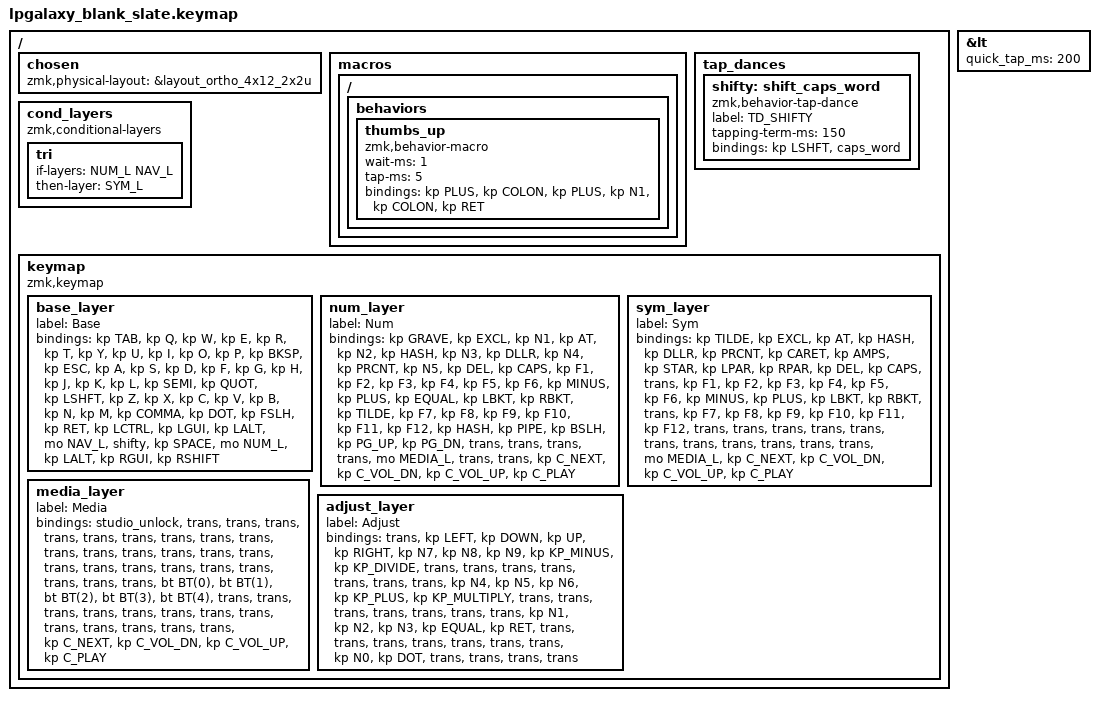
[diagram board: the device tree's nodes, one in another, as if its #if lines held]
/*
 * Copyright (c) 2022 Pete Johanson
 *
 * SPDX-License-Identifier: MIT
 */

#include <behaviors.dtsi>
#include <dt-bindings/zmk/keys.h>
#include <dt-bindings/zmk/bt.h>
#include <dt-bindings/zmk/outputs.h>

#define QWERTY_BASE 1

//#define TBLE_ORTHO   1
#define TBLE_MIT     1
// #define TBLE_DUAL_2U 1

// #define NAV_L 1
#define NUM_L 1
#define SYM_L 2
#define MEDIA_L 3
#define ADJUST_L 4


// Using layer taps on thumbs, having quick tap as well helps w/ repeating space/backspace
&lt { quick_tap_ms = <200>; };

#define BT(n) BT_SEL n

/ {
    chosen {
       zmk,physical-layout =
#ifdef TBLE_DUAL_2U
                       &layout_ortho_4x12_2x2u;
#elif defined(TBLE_MIT)
                       &layout_ortho_4x12_1x2u;
#else
                       &layout_ortho_4x12_all1u;
#endif
    };

    macros {
      ZMK_MACRO(thumbs_up,
		wait-ms = <1>;
		tap-ms = <5>;
                bindings = <&kp PLUS &kp COLON &kp PLUS &kp N1 &kp COLON &kp RET>;
		)
    };
    
    tap_dances {
    	shifty: shift_caps_word {
		compatible = "zmk,behavior-tap-dance";
		label = "TD_SHIFTY";
		#binding-cells = <0>;
		tapping-term-ms = <150>;
		bindings = <&kp LSHFT>, <&caps_word>;
	};
    };

// Conditional layer only when we have less thumb keys
#ifdef TBLE_DUAL_2U
    cond_layers {
        compatible = "zmk,conditional-layers";
	tri {
	    if-layers = <NUM_L NAV_L>;
	    then-layer = <SYM_L>;
        };
    };
#endif

    keymap {
        compatible = "zmk,keymap";

        base_layer {
            label = "Base";
            bindings = <
#ifdef QWERTY_BASE
 &kp TAB    &kp Q      &kp W      &kp E       &kp R          &kp T          &kp Y            &kp U          &kp I       &kp O      &kp P         &kp BKSP
 &kp ESC    &kp A      &kp S      &kp D       &kp F          &kp G          &kp H            &kp J          &kp K       &kp L      &kp SEMI      &kp QUOT
 &kp LSHFT  &kp Z      &kp X      &kp C       &kp V          &kp B          &kp N            &kp M          &kp COMMA   &kp DOT    &kp FSLH      &kp RET

#else
 &kp ESC    &kp Q      &kp W      &kp F       &kp P          &kp B          &kp J            &kp L          &kp U       &kp Y      &kp QUOT      &kp BKSP
 &kp TAB    &kp A      &kp R      &kp S       &kp T          &kp G          &kp M            &kp N          &kp E       &kp I      &kp O         &kp QUOT
 &kp LSHFT  &kp Z      &kp X      &kp C       &kp D          &kp V          &kp K            &kp H          &kp COMMA   &kp DOT    &kp SEMI      &kp RET
#endif
#ifdef TBLE_DUAL_2U
 &kp LCTRL  &kp LGUI   &kp LALT   &mo NAV_L         &shifty                        &kp SPACE                &mo NUM_L   &kp LALT   &kp RGUI      &kp RSHIFT

#elif defined(TBLE_MIT)
// &kp LCTRL  &mo SYM_L   &kp LGUI  &kp LALT    &mo NAV_L          &kp SPACE                   &mo NUM_L      &kp LEFT    &kp DOWN     &kp UP      &kp RIGHT
// &kp LCTRL  &kp LGUI  &kp LALT  &tog ADJUST_L  &mo SYM_L            &kp SPACE                   &mo NUM_L      &kp LEFT    &kp DOWN     &kp UP      &kp RIGHT
   &kp LCTRL  &kp LGUI  &kp LALT  &mo ADJUST_L  &mo SYM_L            &kp SPACE                &mo NUM_L      &kp LEFT    &kp DOWN     &kp UP      &kp RIGHT
#else
&kp LCTRL  &mo SYM_L   &kp LGUI  &kp LALT    &mo NAV_L      &kp SPACE      &kp RET          &mo NUM_L      &kp LEFT    &kp UP     &kp DOWN      &kp RIGHT
//   &kp LCTRL  &kp LGUI  &kp LALT  &tog ADJUST_L  &mo SYM_L            &kp SPACE              &mo NUM_L      &kp LEFT    &kp DOWN     &kp UP      &kp RIGHT
#endif
            >;
        };
//           --------------------------- NEW NUM ---------------------------
num_layer {
    label = "Num";
    bindings = <
 &kp GRAVE   &kp EXCL  &kp N1     &kp AT      &kp N2         &kp HASH       &kp N3           &kp DLLR       &kp N4      &kp PRCNT  &kp N5        &kp DEL
 &kp CAPS    &kp F1    &kp F2     &kp F3      &kp F4         &kp F5         &kp F6           &kp MINUS      &kp PLUS    &kp EQUAL  &kp LBKT      &kp RBKT
 &kp TILDE   &kp F7    &kp F8     &kp F9      &kp F10        &kp F11        &kp F12          &kp HASH       &kp PIPE    &kp BSLH   &kp PG_UP     &kp PG_DN
 &trans      &trans    &trans     &trans      &mo MEDIA_L            &trans                  &trans         &kp C_NEXT  &kp C_VOL_DN &kp C_VOL_UP &kp C_PLAY
    >;
};

//           --------------------------- NEW SYM ---------------------------
sym_layer {
    label = "Sym";
    bindings = <
 &kp TILDE  &kp EXCL   &kp AT     &kp HASH    &kp DLLR       &kp PRCNT      &kp CARET        &kp AMPS       &kp STAR    &kp LPAR   &kp RPAR      &kp DEL
 &kp CAPS   &trans     &kp F1     &kp F2      &kp F3         &kp F4         &kp F5           &kp F6         &kp MINUS   &kp PLUS   &kp LBKT      &kp RBKT
 &trans     &kp F7     &kp F8     &kp F9      &kp F10        &kp F11        &kp F12          &trans         &trans      &trans     &trans        &trans
 &trans     &trans     &trans     &trans      &trans                &trans                   &mo MEDIA_L    &kp C_NEXT  &kp C_VOL_DN &kp C_VOL_UP &kp C_PLAY
    >;
};
//           --------------------------- NEW MEDIA ---------------------------
media_layer {
    label = "Media";
    bindings = <
 &studio_unlock     &trans     &trans     &trans      &trans         &trans         &trans           &trans         &trans      &trans     &trans        &trans
 &trans     &trans     &trans     &trans      &trans         &trans         &trans           &trans         &trans      &trans     &trans        &trans
 &trans     &bt BT(0)  &bt BT(1)  &bt BT(2)   &bt BT(3)      &bt BT(4)      &trans           &trans         &trans      &trans     &trans        &trans
 &trans     &trans     &trans     &trans      &trans                 &trans                  &trans         &kp C_NEXT  &kp C_VOL_DN &kp C_VOL_UP &kp C_PLAY
    >;
};
//           --------------------------- NEW ADJUST ---------------------------
adjust_layer {
    label = "Adjust";
    bindings = <
&trans     &kp LEFT   &kp DOWN   &kp UP      &kp RIGHT       &kp N7          &kp N8          &kp N9          &kp KP_MINUS      &kp KP_DIVIDE       &trans        &trans
&trans     &trans     &trans     &trans      &trans          &kp N4          &kp N5          &kp N6          &kp KP_PLUS       &kp KP_MULTIPLY     &trans        &trans
&trans     &trans     &trans     &trans      &trans          &kp N1          &kp N2          &kp N3          &kp EQUAL         &kp RET             &trans        &trans
&trans     &trans     &trans     &trans      &trans                 &kp N0                   &kp DOT         &trans            &trans              &trans        &trans
    >;
};
    };
};

//           --------------------------- OLD NAV ---------------------------
//        nav_layer {
//            label = "Nav";
//            bindings = <
//&bt BT_CLR &trans     &trans     &trans      &trans          &trans       &trans     &trans         &trans      &trans     &trans     &kp DEL
//&trans     &trans     &trans     &trans      &trans          &trans       &trans     &kp LEFT       &kp DOWN    &kp UP     &kp RIGHT  &trans
//&trans     &bt BT(0)  &bt BT(1)  &bt BT(2)   &bt BT(3)       &bt BT(4)    &trans     &kp HOME       &kp PG_DN   &kp PG_UP  &kp END    &trans
//#ifdef TBLE_DUAL_2U
//&trans  &trans        &trans     &trans              &trans                    &trans       &trans         &trans &trans &trans
//#elif defined(TBLE_MIT)
//&trans  &trans        &trans     &trans      &trans                &trans             &trans      &trans   &trans &trans &trans
//#else
//&trans  &trans        &trans     &trans      &trans          &trans       &trans    &trans  &trans         &trans &trans &trans
//#endif
//            >;
//        };
//           --------------------------- OLD NUM ---------------------------
//        num_layer {
//            label = "Num";
//            bindings = <
// &trans     &kp LBKT   &trans &trans &trans    &kp RBKT    &kp C_PREV    &kp N7     &kp N8      &kp N9       &trans     &trans
// &trans     &kp MINUS  &trans &trans &trans    &kp EQUAL   &kp C_NEXT    &kp N4     &kp N5      &kp N6       &trans     &trans
// &trans     &kp GRAVE  &trans &trans &trans    &kp BSLH    &trans        &kp N1     &kp N2      &kp N3       &trans     &trans
// #ifdef TBLE_DUAL_2U
// &trans  &trans       &trans     &kp N0              &trans                 &trans            &trans         &trans &trans &trans
// #elif defined(TBLE_MIT)
// &trans  &trans       &trans     &kp N0      &trans           &none            &trans        &kp DEL      &trans &trans &trans
// #else
// &trans  &trans       &trans     &kp N0      &trans    &none         &none     &kp ESC        &kp DEL      &trans &trans &trans
// #endif
//             >;
//         };
//           --------------------------- OLD SYM ---------------------------
//        sym_layer {
//            label = "Sym";
//            bindings = <
// &trans     &kp LBRC   &kp AMPS   &kp STAR    &kp LPAR     &kp RBRC     &trans     &trans    &trans       &trans       &trans     &bootloader
// &trans     &kp COLON  &kp DLLR   &kp PRCNT   &kp CARET    &kp PLUS     &trans     &trans    &trans       &trans       &trans     &trans
// &trans     &kp TILDE  &kp EXCL   &kp AT      &kp HASH     &kp PIPE     &trans     &trans    &trans       &trans       &trans     &trans
// #ifdef TBLE_DUAL_2U
// &trans &trans        &trans     &kp RPAR                &trans                    &trans       &trans         &trans &trans &trans
// #elif defined(TBLE_MIT)
// &trans &trans        &trans     &kp RPAR        &trans                &trans             &trans      &trans   &trans &trans &trans
// #else
// &trans &trans        &trans     &kp RPAR        &trans          &trans       &trans    &trans  &trans         &trans &trans &trans
// #endif
//            >;
//        };
